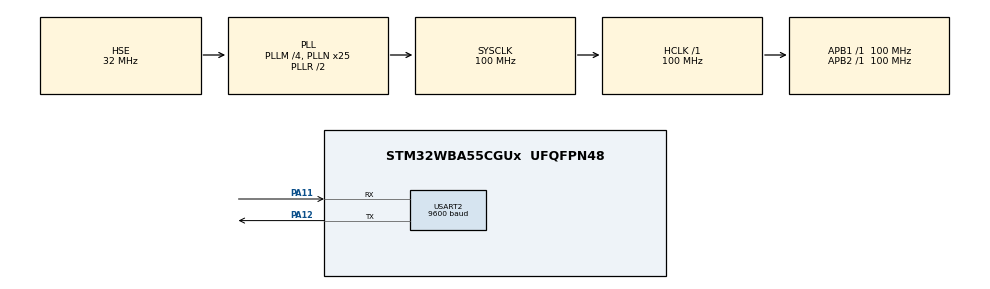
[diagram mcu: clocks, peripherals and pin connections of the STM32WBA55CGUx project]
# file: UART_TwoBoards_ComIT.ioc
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CORTEX_M33_NS.userName=CORTEX_M33
Mcu.Family=STM32WBA
Mcu.Name=STM32WBA55CGUx
Mcu.Package=UFQFPN48
NVIC.PriorityGroup=NVIC_PRIORITYGROUP_4
NVIC.USART2_IRQn=true\:0\:0\:false\:false\:true\:true\:true\:true
OSC_IN.Mode=HSE-External-Oscillator
OSC_IN.Signal=RCC_OSC_IN
OSC_OUT.Mode=HSE-External-Oscillator
OSC_OUT.Signal=RCC_OSC_OUT
PA11.GPIO_PuPd=GPIO_PULLUP
PA11.Mode=Asynchronous
PA11.Signal=USART2_RX
PA12.GPIO_PuPd=GPIO_PULLUP
PA12.Mode=Asynchronous
PA12.Signal=USART2_TX
ProjectManager.HeapSize=0x200
ProjectManager.StackSize=0x400
ProjectManager.TargetToolchain=EWARM V9.20
RCC.ADCFreq_Value=100000000
RCC.AHB5CLKDivider=DIV4
RCC.AHBFreq_Value=100000000
RCC.APB1Freq_Value=100000000
RCC.APB1TimFreq_Value=100000000
RCC.APB2Freq_Value=100000000
RCC.APB2TimFreq_Value=100000000
RCC.CortexFreq_Value=12500000
RCC.HCLKFreq_Value=100000000
RCC.HSE_VALUE=32000000
RCC.HSI_VALUE=16000000
RCC.LSE_VALUE=32768
RCC.LSI1_VALUE=32000
RCC.LSI2_VALUE=32000
RCC.PLLFRACN=0
RCC.PLLM=4
RCC.PLLN=25
RCC.PLLSourceVirtual=RCC_PLLSOURCE_HSE
RCC.SYSCLKFreq_VALUE=100000000
RCC.SYSCLKSourceVirtual=RCC_SYSCLKSOURCE_PLLCLK
RCC.VCOOutputFreq_Value=200000000
USART2.AutoBaudRateEnableParam=UART_ADVFEATURE_AUTOBAUDRATE_DISABLE
USART2.BaudRate=9600
USART2.DMADisableonRxErrorParam=ADVFEATURE_DMA_ENABLEONRXERROR
USART2.DataInvertParam=ADVFEATURE_DATAINV_DISABLE
USART2.MSBFirstParam=ADVFEATURE_MSBFIRST_DISABLE
USART2.Mode=MODE_TX_RX
USART2.OneBitSampling=UART_ONE_BIT_SAMPLE_DISABLE
USART2.OverSampling=UART_OVERSAMPLING_16
USART2.OverrunDisableParam=ADVFEATURE_OVERRUN_ENABLE
USART2.Parity=PARITY_NONE
USART2.RxPinLevelInvertParam=ADVFEATURE_RXINV_DISABLE
USART2.StopBits=STOPBITS_1
USART2.SwapParam=ADVFEATURE_SWAP_DISABLE
USART2.TxPinLevelInvertParam=ADVFEATURE_TXINV_DISABLE
USART2.VirtualMode-Asynchronous=VM_ASYNC
USART2.WordLength=WORDLENGTH_8B
VP_CORTEX_M33_NS_VS_Hclk.Mode=Hclk_Mode
VP_ICACHE_VS_ICACHE.Mode=DirectMappedCache
VP_MEMORYMAP_VS_MEMORYMAP.Mode=CurAppReg
VP_PWR_VS_SECSignals.Mode=Security/Privilege
board=custom

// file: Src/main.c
/* USER CODE BEGIN Header */
/**
  * @file    UART/UART_TwoBoards_ComIT/Src/main.c
  * @author  MCD Application Team
  * @brief   This sample code shows how to use UART HAL API to transmit
  *          and receive a data buffer with a communication process based on
  *          IT transfer.
  *          The communication is done using 2 Boards.
  ******************************************************************************
  * @attention
  *
  * Copyright (c) 2022 STMicroelectronics.
  * All rights reserved.
  *
  * This software is licensed under terms that can be found in the LICENSE file
  * in the root directory of this software component.
  * If no LICENSE file comes with this software, it is provided AS-IS.
  *
  ******************************************************************************
  */
/* USER CODE END Header */
#include "main.h"

/* USER CODE BEGIN PD */
#define TRANSMITTER_BOARD
/* USER CODE END PD */

UART_HandleTypeDef huart2;

/* USER CODE BEGIN PV */
__IO ITStatus UartReady = RESET;
__IO uint32_t UserButtonStatus = 0;  /* set to 1 after User Button interrupt  */

/* Buffer used for transmission */
uint8_t aTxBuffer[] = " ****UART_TwoBoards_ComIT****  ****UART_TwoBoards_ComIT****  ****UART_TwoBoards_ComIT**** ";

/* Buffer used for reception */
uint8_t aRxBuffer[RXBUFFERSIZE];

/* USER CODE END PV */

void SystemClock_Config(void);
static void MX_GPIO_Init(void);
static void MX_ICACHE_Init(void);
static void MX_USART2_UART_Init(void);
/* USER CODE BEGIN PFP */
static uint16_t Buffercmp(uint8_t *pBuffer1, uint8_t *pBuffer2, uint16_t BufferLength);
/* USER CODE END PFP */

int main(void)
{

  /* USER CODE BEGIN 1 */
  /* STM32WBAxx HAL library initialization:
       - Systick timer is configured by default as source of time base, but user
             can eventually implement his proper time base source (a general purpose
             timer for example or other time source), keeping in mind that Time base
             duration should be kept 1ms since PPP_TIMEOUT_VALUEs are defined and
             handled in milliseconds basis.
       - Set NVIC Group Priority to 4
       - Low Level Initialization
     */
  /* USER CODE END 1 */

  /* MCU Configuration--------------------------------------------------------*/

  /* Reset of all peripherals, Initializes the Flash interface and the Systick. */
  HAL_Init();

  /* Configure the system clock */
  SystemClock_Config();

  /* Initialize all configured peripherals */
  MX_GPIO_Init();
  MX_ICACHE_Init();
  MX_USART2_UART_Init();
  /* USER CODE BEGIN 2 */
  /* Configure LD1 and LD3 */
  BSP_LED_Init(LD1);
  BSP_LED_Init(LD3);

#ifdef TRANSMITTER_BOARD

  /* Configure USER push-button in Interrupt mode */
  BSP_PB_Init(B1, BUTTON_MODE_EXTI);

  /* Wait for USER push-button press before starting the Communication.
     In the meantime, LD1 is blinking */
  while (UserButtonStatus == 0)
  {
    /* Toggle LD1*/
    BSP_LED_Toggle(LD1);
    HAL_Delay(100);
  }

  BSP_LED_Off(LD1);

  /* The board sends the message and expects to receive it back */

  /*##-1- Start the transmission process #####################################*/
  /* While the UART in reception process, user can transmit data through
     "aTxBuffer" buffer */
  if (HAL_UART_Transmit_IT(&huart2, (uint8_t *)aTxBuffer, TXBUFFERSIZE) != HAL_OK)
  {
    Error_Handler();
  }

  /*##-2- Wait for the end of the transfer ###################################*/
  while (UartReady != SET)
  {
  }

  /* Reset transmission flag */
  UartReady = RESET;

  /*##-3- Put UART peripheral in reception process ###########################*/
  if (HAL_UART_Receive_IT(&huart2, (uint8_t *)aRxBuffer, RXBUFFERSIZE) != HAL_OK)
  {
    Error_Handler();
  }

#else

  /* The board receives the message and sends it back */

  /*##-1- Put UART peripheral in reception process ###########################*/
  if (HAL_UART_Receive_IT(&huart2, (uint8_t *)aRxBuffer, RXBUFFERSIZE) != HAL_OK)
  {
    Error_Handler();
  }

  /*##-2- Wait for the end of the transfer ###################################*/
  /* While waiting for message to come from the other board, LD1 is
     blinking according to the following pattern: a double flash every half-second */
  while (UartReady != SET)
  {
    BSP_LED_On(LD1);
    HAL_Delay(100);
    BSP_LED_Off(LD1);
    HAL_Delay(100);
    BSP_LED_On(LD1);
    HAL_Delay(100);
    BSP_LED_Off(LD1);
    HAL_Delay(500);
  }

  /* Reset transmission flag */
  UartReady = RESET;
  BSP_LED_Off(LD1);

  /*##-3- Start the transmission process #####################################*/
  /* While the UART in reception process, user can transmit data through
     "aTxBuffer" buffer */
  if (HAL_UART_Transmit_IT(&huart2, (uint8_t *)aTxBuffer, TXBUFFERSIZE) != HAL_OK)
  {
    Error_Handler();
  }

#endif /* TRANSMITTER_BOARD */

  /*##-4- Wait for the end of the transfer ###################################*/
  while (UartReady != SET)
  {
  }

  /* Reset transmission flag */
  UartReady = RESET;

  /*##-5- Compare the sent and received buffers ##############################*/
  if (Buffercmp((uint8_t *)aTxBuffer, (uint8_t *)aRxBuffer, RXBUFFERSIZE))
  {
    Error_Handler();
  }

  /* Turn on LD1 if test passes then enter infinite loop */
  BSP_LED_On(LD1);

  /* USER CODE END 2 */

  /* Infinite loop */
  while (1)
  {

  }
}

void SystemClock_Config(void)
{
  RCC_OscInitTypeDef RCC_OscInitStruct = {0};
  RCC_ClkInitTypeDef RCC_ClkInitStruct = {0};

  /** Supply configuration update enable
  */
  HAL_PWREx_ConfigSupply(PWR_LDO_SUPPLY);

  /** Configure the main internal regulator output voltage
  */
  if (HAL_PWREx_ControlVoltageScaling(PWR_REGULATOR_VOLTAGE_SCALE1) != HAL_OK)
  {
    Error_Handler();
  }

  /** Initializes the CPU, AHB and APB busses clocks
  */
  RCC_OscInitStruct.OscillatorType = RCC_OSCILLATORTYPE_HSE;
  RCC_OscInitStruct.HSEState = RCC_HSE_ON;
  RCC_OscInitStruct.HSEDiv = RCC_HSE_DIV1;
  RCC_OscInitStruct.PLL1.PLLState = RCC_PLL_ON;
  RCC_OscInitStruct.PLL1.PLLSource = RCC_PLLSOURCE_HSE;
  RCC_OscInitStruct.PLL1.PLLM = 4;
  RCC_OscInitStruct.PLL1.PLLN = 25;
  RCC_OscInitStruct.PLL1.PLLP = 2;
  RCC_OscInitStruct.PLL1.PLLQ = 2;
  RCC_OscInitStruct.PLL1.PLLR = 2;
  RCC_OscInitStruct.PLL1.PLLFractional = 0;
  if (HAL_RCC_OscConfig(&RCC_OscInitStruct) != HAL_OK)
  {
    Error_Handler();
  }

  /** Initializes the CPU, AHB and APB busses clocks
  */
  RCC_ClkInitStruct.ClockType = RCC_CLOCKTYPE_HCLK|RCC_CLOCKTYPE_SYSCLK
                              |RCC_CLOCKTYPE_PCLK1|RCC_CLOCKTYPE_PCLK2
                              |RCC_CLOCKTYPE_PCLK7|RCC_CLOCKTYPE_HCLK5;
  RCC_ClkInitStruct.SYSCLKSource = RCC_SYSCLKSOURCE_PLLCLK;
  RCC_ClkInitStruct.AHBCLKDivider = RCC_SYSCLK_DIV1;
  RCC_ClkInitStruct.APB1CLKDivider = RCC_HCLK_DIV1;
  RCC_ClkInitStruct.APB2CLKDivider = RCC_HCLK_DIV1;
  RCC_ClkInitStruct.APB7CLKDivider = RCC_HCLK_DIV1;
  RCC_ClkInitStruct.AHB5_PLL1_CLKDivider = RCC_SYSCLK_PLL1_DIV4;
  RCC_ClkInitStruct.AHB5_HSEHSI_CLKDivider = RCC_SYSCLK_HSEHSI_DIV1;

  if (HAL_RCC_ClockConfig(&RCC_ClkInitStruct, FLASH_LATENCY_3) != HAL_OK)
  {
    Error_Handler();
  }
}

static void MX_ICACHE_Init(void)
{

  /** Enable instruction cache in 1-way (direct mapped cache)
  */
  if (HAL_ICACHE_ConfigAssociativityMode(ICACHE_1WAY) != HAL_OK)
  {
    Error_Handler();
  }
  if (HAL_ICACHE_Enable() != HAL_OK)
  {
    Error_Handler();
  }

}

static void MX_USART2_UART_Init(void)
{

  huart2.Instance = USART2;
  huart2.Init.BaudRate = 9600;
  huart2.Init.WordLength = UART_WORDLENGTH_8B;
  huart2.Init.StopBits = UART_STOPBITS_1;
  huart2.Init.Parity = UART_PARITY_NONE;
  huart2.Init.Mode = UART_MODE_TX_RX;
  huart2.Init.HwFlowCtl = UART_HWCONTROL_NONE;
  huart2.Init.OverSampling = UART_OVERSAMPLING_16;
  huart2.Init.OneBitSampling = UART_ONE_BIT_SAMPLE_DISABLE;
  huart2.Init.ClockPrescaler = UART_PRESCALER_DIV1;
  huart2.AdvancedInit.AdvFeatureInit = UART_ADVFEATURE_NO_INIT;
  if (HAL_UART_Init(&huart2) != HAL_OK)
  {
    Error_Handler();
  }
  if (HAL_UARTEx_SetTxFifoThreshold(&huart2, UART_TXFIFO_THRESHOLD_1_8) != HAL_OK)
  {
    Error_Handler();
  }
  if (HAL_UARTEx_SetRxFifoThreshold(&huart2, UART_RXFIFO_THRESHOLD_1_8) != HAL_OK)
  {
    Error_Handler();
  }
  if (HAL_UARTEx_DisableFifoMode(&huart2) != HAL_OK)
  {
    Error_Handler();
  }

}

static void MX_GPIO_Init(void)
{

  /* GPIO Ports Clock Enable */
  __HAL_RCC_GPIOA_CLK_ENABLE();

}

/* USER CODE BEGIN 4 */
/**
  * @brief  Tx Transfer completed callback
  * @param  UartHandle: UART handle.
  * @note   This example shows a simple way to report end of IT Tx transfer, and
  *         you can add your own implementation.
  * @retval None
  */
void HAL_UART_TxCpltCallback(UART_HandleTypeDef *UartHandle)
{
  /* Set transmission flag: transfer complete */
  UartReady = SET;

}

/**
  * @brief  Rx Transfer completed callback
  * @param  UartHandle: UART handle
  * @note   This example shows a simple way to report end of DMA Rx transfer, and
  *         you can add your own implementation.
  * @retval None
  */
void HAL_UART_RxCpltCallback(UART_HandleTypeDef *UartHandle)
{
  /* Set transmission flag: transfer complete */
  UartReady = SET;

}

/**
  * @brief  UART error callbacks
  * @param  UartHandle: UART handle
  * @note   This example shows a simple way to report transfer error, and you can
  *         add your own implementation.
  * @retval None
  */
void HAL_UART_ErrorCallback(UART_HandleTypeDef *UartHandle)
{
  Error_Handler();
}

/**
  * @brief EXTI line detection callbacks
  * @param GPIO_Pin: Specifies the pins connected EXTI line
  * @retval None
  */
void HAL_GPIO_EXTI_Falling_Callback(uint16_t GPIO_Pin)
{
  if (GPIO_Pin == B1_PIN)
  {
    UserButtonStatus = 1;
  }
}
/**
  * @brief  Compares two buffers.
  * @param  pBuffer1, pBuffer2: buffers to be compared.
  * @param  BufferLength: buffer's length
  * @retval 0  : pBuffer1 identical to pBuffer2
  *         >0 : pBuffer1 differs from pBuffer2
  */
static uint16_t Buffercmp(uint8_t *pBuffer1, uint8_t *pBuffer2, uint16_t BufferLength)
{
  while (BufferLength--)
  {
    if ((*pBuffer1) != *pBuffer2)
    {
      return BufferLength;
    }
    pBuffer1++;
    pBuffer2++;
  }

  return 0;
}

/* USER CODE END 4 */

void Error_Handler(void)
{
  /* USER CODE BEGIN Error_Handler_Debug */
  /* User can add his own implementation to report the HAL error return state */
  /* Turn LD3 on */
  BSP_LED_On(LD3);
  while (1);
  /* USER CODE END Error_Handler_Debug */
}
